VERSION ""

NS_ :

BS_:

BU_:

BO_ 3221225472 VECTOR__INDEPENDENT_SIG_MSG: 0 Vector__XXX
 SG_ Unknown_176_4 : 32|8@1+ (1,0) [0|0] "" Vector__XXX
 SG_ NewSignal_0024 : 32|8@1+ (1,0) [0|0] "" Vector__XXX
 SG_ Unknown_215_6 : 0|8@1+ (1,0) [0|0] "" Vector__XXX

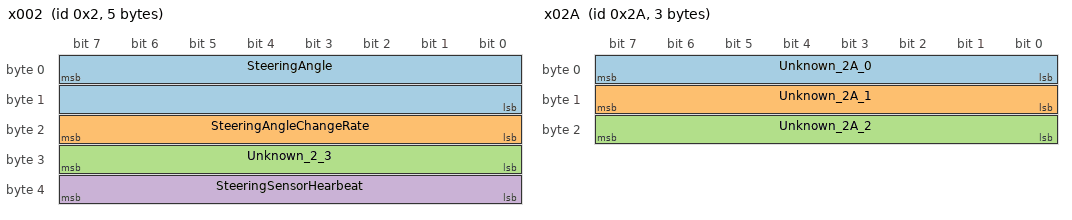
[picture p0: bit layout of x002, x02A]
BO_ 2 x002: 5 Vector__XXX
 SG_ SteeringAngle : 7|16@0+ (1,0) [0|0] "ddeg" Vector__XXX
 SG_ SteeringAngleChangeRate : 23|8@0+ (1,0) [0|0] "" Vector__XXX
 SG_ Unknown_2_3 : 31|8@0+ (1,0) [0|0] "" Vector__XXX
 SG_ SteeringSensorHearbeat : 39|8@0+ (1,0) [0|0] "" Vector__XXX

BO_ 42 x02A: 3 Vector__XXX
 SG_ Unknown_2A_0 : 0|8@1+ (1,0) [0|0] "" Vector__XXX
 SG_ Unknown_2A_1 : 8|8@1+ (1,0) [0|0] "" Vector__XXX
 SG_ Unknown_2A_2 : 16|8@1+ (1,0) [0|0] "" Vector__XXX

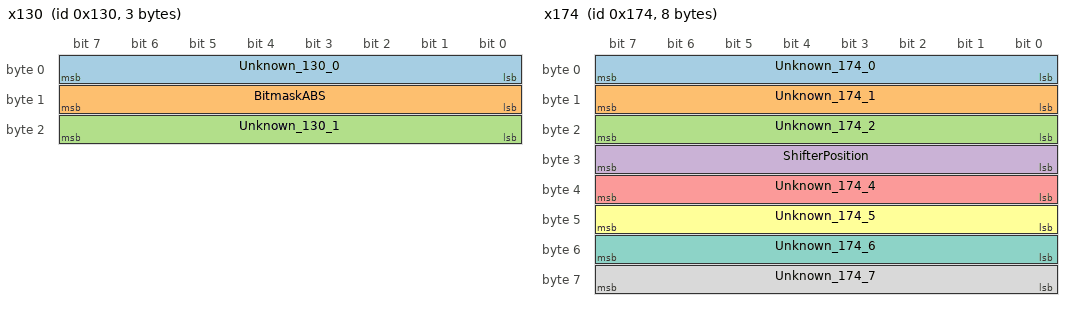
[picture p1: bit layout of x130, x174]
BO_ 304 x130: 3 Vector__XXX
 SG_ Unknown_130_0 : 0|8@1+ (1,0) [0|0] "" Vector__XXX
 SG_ BitmaskABS : 8|8@1+ (1,0) [0|0] "" Vector__XXX
 SG_ Unknown_130_1 : 16|8@1+ (1,0) [0|0] "" Vector__XXX

BO_ 372 x174: 8 Vector__XXX
 SG_ Unknown_174_0 : 0|8@1+ (1,0) [0|0] "" Vector__XXX
 SG_ Unknown_174_1 : 8|8@1+ (1,0) [0|0] "" Vector__XXX
 SG_ Unknown_174_2 : 16|8@1+ (1,0) [0|0] "" Vector__XXX
 SG_ ShifterPosition : 24|8@1+ (1,0) [0|0] "" Vector__XXX
 SG_ Unknown_174_4 : 32|8@1+ (1,0) [0|0] "" Vector__XXX
 SG_ Unknown_174_5 : 40|8@1+ (1,0) [0|0] "" Vector__XXX
 SG_ Unknown_174_6 : 48|8@1+ (1,0) [0|0] "" Vector__XXX
 SG_ Unknown_174_7 : 56|8@1+ (1,0) [0|0] "" Vector__XXX

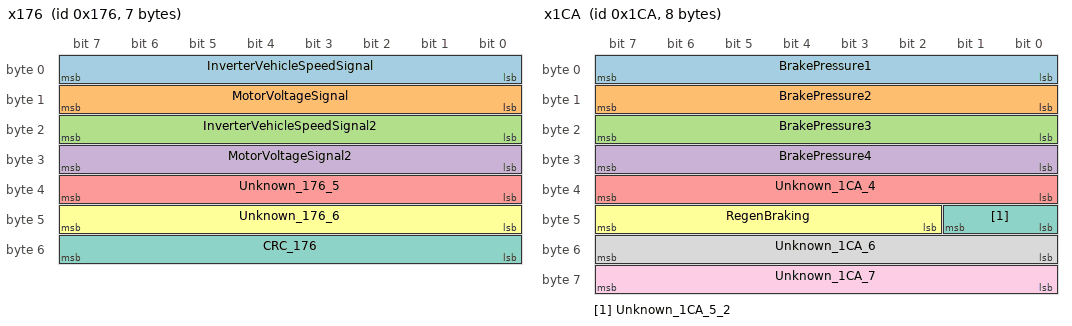
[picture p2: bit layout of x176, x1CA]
BO_ 374 x176: 7 Vector__XXX
 SG_ InverterVehicleSpeedSignal : 0|8@1+ (1,0) [0|0] "" Vector__XXX
 SG_ MotorVoltageSignal : 8|8@1+ (1,0) [0|0] "" Vector__XXX
 SG_ InverterVehicleSpeedSignal2 : 16|8@1+ (1,0) [0|0] "" Vector__XXX
 SG_ MotorVoltageSignal2 : 24|8@1+ (1,0) [0|0] "" Vector__XXX
 SG_ Unknown_176_5 : 32|8@1+ (1,0) [0|0] "" Vector__XXX
 SG_ Unknown_176_6 : 40|8@1+ (1,0) [0|0] "" Vector__XXX
 SG_ CRC_176 : 48|8@1+ (1,0) [0|0] "" Vector__XXX

BO_ 384 x180: 8 Vector__XXX
 SG_ Unknown_180_0 : 0|8@1+ (1,0) [0|0] "" Vector__XXX
 SG_ Unknown_180_1 : 8|8@1+ (1,0) [0|0] "" Vector__XXX
 SG_ MotorAmp : 23|16@0+ (1,0) [0|0] "" Vector__XXX
 SG_ MotorAmpAlternative : 32|8@1+ (1,0) [0|0] "" Vector__XXX
 SG_ ThrottlePosition : 40|8@1+ (1,0) [0|0] "" Vector__XXX
 SG_ Unknown_180_5 : 48|8@1+ (1,0) [0|0] "" Vector__XXX
 SG_ Unknown_180_6 : 56|8@1+ (1,0) [0|0] "" Vector__XXX
 SG_ Unknown_180_7 : 0|8@1+ (1,0) [0|0] "" Vector__XXX

BO_ 458 x1CA: 8 Vector__XXX
 SG_ BrakePressure1 : 0|8@1+ (1,0) [0|0] "" Vector__XXX
 SG_ BrakePressure2 : 8|8@1+ (1,0) [0|0] "" Vector__XXX
 SG_ BrakePressure3 : 16|8@1+ (1,0) [0|0] "" Vector__XXX
 SG_ BrakePressure4 : 24|8@1+ (1,0) [0|0] "" Vector__XXX
 SG_ Unknown_1CA_4 : 32|8@1+ (1,0) [0|0] "" Vector__XXX
 SG_ RegenBraking : 42|6@1+ (1,0) [0|0] "" Vector__XXX
 SG_ Unknown_1CA_5_2 : 40|2@1+ (1,0) [0|0] "" Vector__XXX
 SG_ Unknown_1CA_6 : 48|8@1+ (1,0) [0|0] "" Vector__XXX
 SG_ Unknown_1CA_7 : 56|8@1+ (1,0) [0|0] "" Vector__XXX

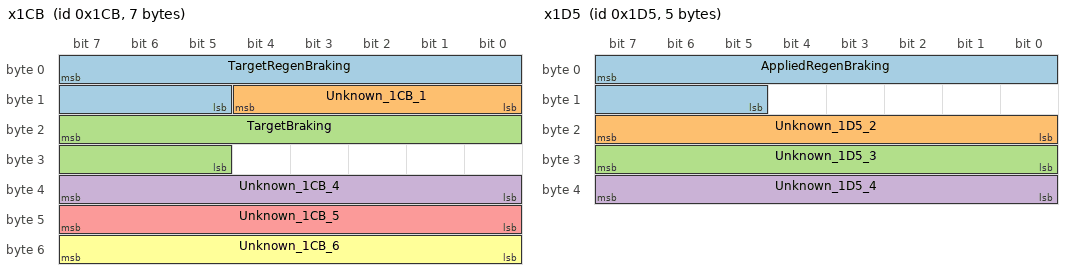
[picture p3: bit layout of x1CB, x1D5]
BO_ 459 x1CB: 7 Vector__XXX
 SG_ TargetRegenBraking : 7|11@0+ (1,0) [0|0] "" Vector__XXX
 SG_ Unknown_1CB_1 : 8|5@1+ (1,0) [0|0] "" Vector__XXX
 SG_ TargetBraking : 23|11@0+ (1,0) [0|0] "" Vector__XXX
 SG_ Unknown_1CB_4 : 32|8@1+ (1,0) [0|0] "" Vector__XXX
 SG_ Unknown_1CB_5 : 40|8@1+ (1,0) [0|0] "" Vector__XXX
 SG_ Unknown_1CB_6 : 48|8@1+ (1,0) [0|0] "" Vector__XXX

BO_ 469 x1D5: 5 Vector__XXX
 SG_ AppliedRegenBraking : 7|11@0+ (1,0) [0|0] "" Vector__XXX
 SG_ Unknown_1D5_2 : 16|8@1+ (1,0) [0|0] "" Vector__XXX
 SG_ Unknown_1D5_3 : 24|8@1+ (1,0) [0|0] "" Vector__XXX
 SG_ Unknown_1D5_4 : 32|8@1+ (1,0) [0|0] "" Vector__XXX

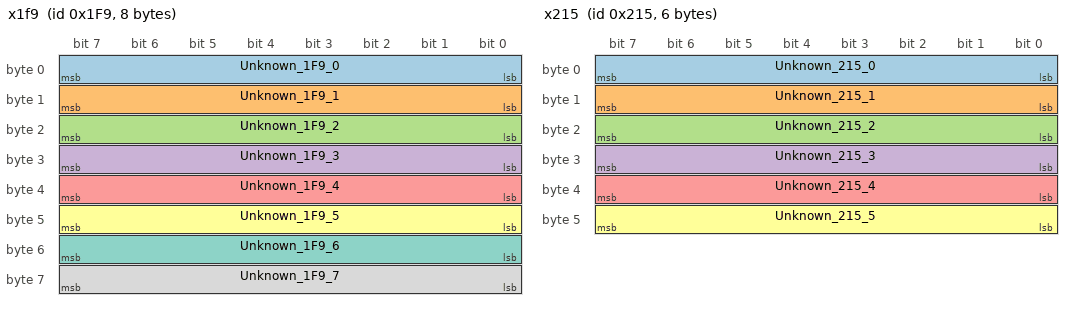
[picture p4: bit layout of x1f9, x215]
BO_ 505 x1f9: 8 Vector__XXX
 SG_ Unknown_1F9_0 : 0|8@1+ (1,0) [0|0] "" Vector__XXX
 SG_ Unknown_1F9_1 : 8|8@1+ (1,0) [0|0] "" Vector__XXX
 SG_ Unknown_1F9_2 : 16|8@1+ (1,0) [0|0] "" Vector__XXX
 SG_ Unknown_1F9_3 : 24|8@1+ (1,0) [0|0] "" Vector__XXX
 SG_ Unknown_1F9_4 : 32|8@1+ (1,0) [0|0] "" Vector__XXX
 SG_ Unknown_1F9_5 : 40|8@1+ (1,0) [0|0] "" Vector__XXX
 SG_ Unknown_1F9_6 : 48|8@1+ (1,0) [0|0] "" Vector__XXX
 SG_ Unknown_1F9_7 : 56|8@1+ (1,0) [0|0] "" Vector__XXX

BO_ 533 x215: 6 Vector__XXX
 SG_ Unknown_215_0 : 0|8@1+ (1,0) [0|0] "" Vector__XXX
 SG_ Unknown_215_1 : 8|8@1+ (1,0) [0|0] "" Vector__XXX
 SG_ Unknown_215_2 : 16|8@1+ (1,0) [0|0] "" Vector__XXX
 SG_ Unknown_215_3 : 24|8@1+ (1,0) [0|0] "" Vector__XXX
 SG_ Unknown_215_4 : 32|8@1+ (1,0) [0|0] "" Vector__XXX
 SG_ Unknown_215_5 : 40|8@1+ (1,0) [0|0] "" Vector__XXX

BO_ 534 x216: 2 Vector__XXX
 SG_ Unknown_216_0 : 0|8@1+ (1,0) [0|0] "" Vector__XXX
 SG_ Unknown_216_1 : 8|8@1+ (1,0) [0|0] "" Vector__XXX

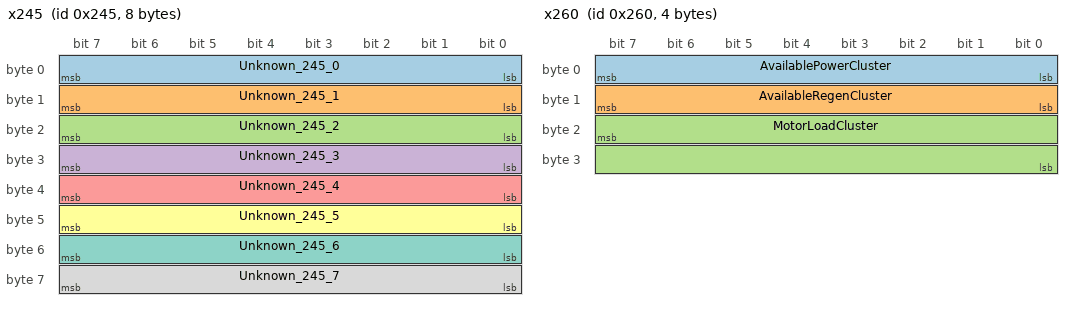
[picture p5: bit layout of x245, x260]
BO_ 581 x245: 8 Vector__XXX
 SG_ Unknown_245_0 : 0|8@1+ (1,0) [0|0] "" Vector__XXX
 SG_ Unknown_245_1 : 8|8@1+ (1,0) [0|0] "" Vector__XXX
 SG_ Unknown_245_2 : 16|8@1+ (1,0) [0|0] "" Vector__XXX
 SG_ Unknown_245_3 : 24|8@1+ (1,0) [0|0] "" Vector__XXX
 SG_ Unknown_245_4 : 32|8@1+ (1,0) [0|0] "" Vector__XXX
 SG_ Unknown_245_5 : 40|8@1+ (1,0) [0|0] "" Vector__XXX
 SG_ Unknown_245_6 : 48|8@1+ (1,0) [0|0] "" Vector__XXX
 SG_ Unknown_245_7 : 56|8@1+ (1,0) [0|0] "" Vector__XXX

BO_ 608 x260: 4 Vector__XXX
 SG_ AvailablePowerCluster : 0|8@1+ (1,0) [0|90] "kW" Vector__XXX
 SG_ AvailableRegenCluster : 8|8@1+ (1,0) [0|50] "kW" Vector__XXX
 SG_ MotorLoadCluster : 23|16@0+ (1,0) [100|16000] "" Vector__XXX

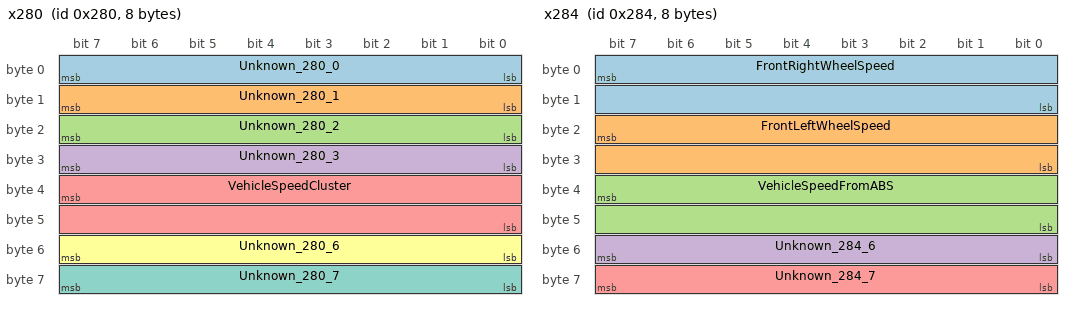
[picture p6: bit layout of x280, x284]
BO_ 640 x280: 8 Vector__XXX
 SG_ Unknown_280_0 : 0|8@1+ (1,0) [0|0] "" Vector__XXX
 SG_ Unknown_280_1 : 8|8@1+ (1,0) [0|0] "" Vector__XXX
 SG_ Unknown_280_2 : 16|8@1+ (1,0) [0|0] "" Vector__XXX
 SG_ Unknown_280_3 : 24|8@1+ (1,0) [0|0] "" Vector__XXX
 SG_ VehicleSpeedCluster : 39|16@0+ (1,0) [0|0] "" Vector__XXX
 SG_ Unknown_280_6 : 48|8@1+ (1,0) [0|0] "" Vector__XXX
 SG_ Unknown_280_7 : 56|8@1+ (1,0) [0|0] "" Vector__XXX

BO_ 644 x284: 8 Vector__XXX
 SG_ FrontRightWheelSpeed : 7|16@0+ (1,0) [0|0] "" Vector__XXX
 SG_ FrontLeftWheelSpeed : 23|16@0+ (1,0) [0|0] "" Vector__XXX
 SG_ VehicleSpeedFromABS : 39|16@0+ (1,0) [0|0] "" Vector__XXX
 SG_ Unknown_284_6 : 48|8@1+ (1,0) [0|0] "" Vector__XXX
 SG_ Unknown_284_7 : 56|8@1+ (1,0) [0|0] "" Vector__XXX

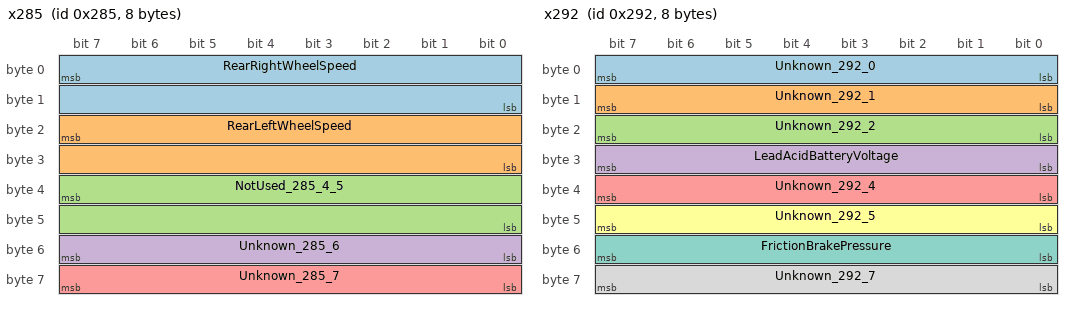
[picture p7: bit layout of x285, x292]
BO_ 645 x285: 8 Vector__XXX
 SG_ RearRightWheelSpeed : 7|16@0+ (1,0) [0|0] "" Vector__XXX
 SG_ RearLeftWheelSpeed : 23|16@0+ (1,0) [0|0] "" Vector__XXX
 SG_ NotUsed_285_4_5 : 39|16@0+ (1,0) [0|0] "" Vector__XXX
 SG_ Unknown_285_6 : 48|8@1+ (1,0) [0|0] "" Vector__XXX
 SG_ Unknown_285_7 : 56|8@1+ (1,0) [0|0] "" Vector__XXX

BO_ 658 x292: 8 Vector__XXX
 SG_ Unknown_292_0 : 0|8@1+ (1,0) [0|0] "" Vector__XXX
 SG_ Unknown_292_1 : 8|8@1+ (1,0) [0|0] "" Vector__XXX
 SG_ Unknown_292_2 : 16|8@1+ (1,0) [0|0] "" Vector__XXX
 SG_ LeadAcidBatteryVoltage : 24|8@1+ (1,0) [0|150] "dV" Vector__XXX
 SG_ Unknown_292_4 : 32|8@1+ (1,0) [0|0] "" Vector__XXX
 SG_ Unknown_292_5 : 40|8@1+ (1,0) [0|0] "" Vector__XXX
 SG_ FrictionBrakePressure : 48|8@1+ (1,0) [0|255] "" Vector__XXX
 SG_ Unknown_292_7 : 56|8@1+ (1,0) [0|0] "" Vector__XXX

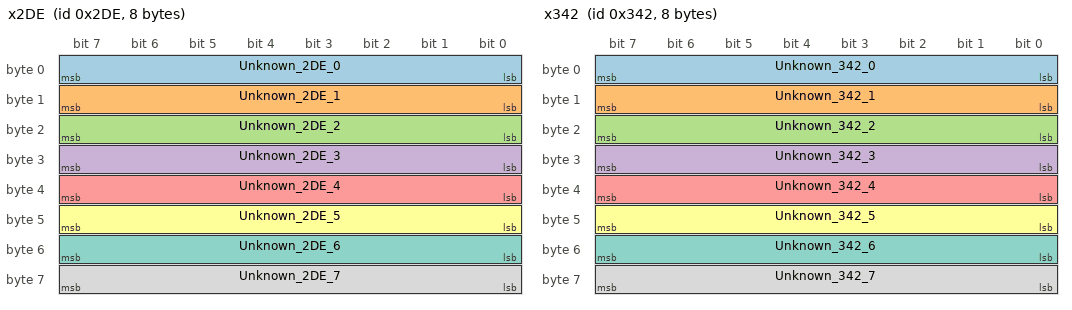
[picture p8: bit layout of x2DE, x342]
BO_ 734 x2DE: 8 Vector__XXX
 SG_ Unknown_2DE_0 : 0|8@1+ (1,0) [0|0] "" Vector__XXX
 SG_ Unknown_2DE_1 : 8|8@1+ (1,0) [0|0] "" Vector__XXX
 SG_ Unknown_2DE_2 : 16|8@1+ (1,0) [0|0] "" Vector__XXX
 SG_ Unknown_2DE_3 : 24|8@1+ (1,0) [0|0] "" Vector__XXX
 SG_ Unknown_2DE_4 : 32|8@1+ (1,0) [0|0] "" Vector__XXX
 SG_ Unknown_2DE_5 : 40|8@1+ (1,0) [0|0] "" Vector__XXX
 SG_ Unknown_2DE_6 : 48|8@1+ (1,0) [0|0] "" Vector__XXX
 SG_ Unknown_2DE_7 : 56|8@1+ (1,0) [0|0] "" Vector__XXX

BO_ 768 x300: 1 Vector__XXX
 SG_ SteeringWheelForce : 0|8@1+ (1,0) [0|0] "" Vector__XXX

BO_ 834 x342: 8 Vector__XXX
 SG_ Unknown_342_0 : 0|8@1+ (1,0) [0|0] "" Vector__XXX
 SG_ Unknown_342_1 : 8|8@1+ (1,0) [0|0] "" Vector__XXX
 SG_ Unknown_342_2 : 16|8@1+ (1,0) [0|0] "" Vector__XXX
 SG_ Unknown_342_3 : 24|8@1+ (1,0) [0|0] "" Vector__XXX
 SG_ Unknown_342_4 : 32|8@1+ (1,0) [0|0] "" Vector__XXX
 SG_ Unknown_342_5 : 40|8@1+ (1,0) [0|0] "" Vector__XXX
 SG_ Unknown_342_6 : 48|8@1+ (1,0) [0|0] "" Vector__XXX
 SG_ Unknown_342_7 : 56|8@1+ (1,0) [0|0] "" Vector__XXX

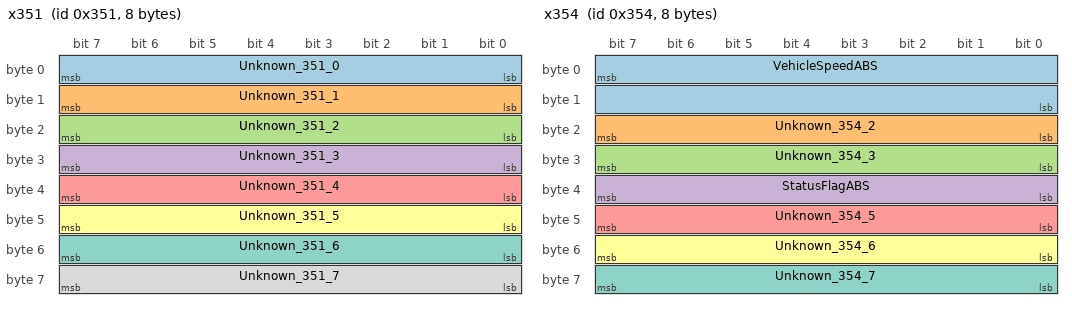
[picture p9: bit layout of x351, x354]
BO_ 849 x351: 8 Vector__XXX
 SG_ Unknown_351_0 : 0|8@1+ (1,0) [0|0] "" Vector__XXX
 SG_ Unknown_351_1 : 8|8@1+ (1,0) [0|0] "" Vector__XXX
 SG_ Unknown_351_2 : 16|8@1+ (1,0) [0|0] "" Vector__XXX
 SG_ Unknown_351_3 : 24|8@1+ (1,0) [0|0] "" Vector__XXX
 SG_ Unknown_351_4 : 32|8@1+ (1,0) [0|0] "" Vector__XXX
 SG_ Unknown_351_5 : 40|8@1+ (1,0) [0|0] "" Vector__XXX
 SG_ Unknown_351_6 : 48|8@1+ (1,0) [0|0] "" Vector__XXX
 SG_ Unknown_351_7 : 56|8@1+ (1,0) [0|0] "" Vector__XXX

BO_ 852 x354: 8 Vector__XXX
 SG_ VehicleSpeedABS : 7|16@0+ (1,0) [0|0] "" Vector__XXX
 SG_ Unknown_354_2 : 16|8@1+ (1,0) [0|0] "" Vector__XXX
 SG_ Unknown_354_3 : 24|8@1+ (1,0) [0|0] "" Vector__XXX
 SG_ StatusFlagABS : 32|8@1+ (1,0) [0|0] "" Vector__XXX
 SG_ Unknown_354_5 : 40|8@1+ (1,0) [0|0] "" Vector__XXX
 SG_ Unknown_354_6 : 48|8@1+ (1,0) [0|0] "" Vector__XXX
 SG_ Unknown_354_7 : 56|8@1+ (1,0) [0|0] "" Vector__XXX

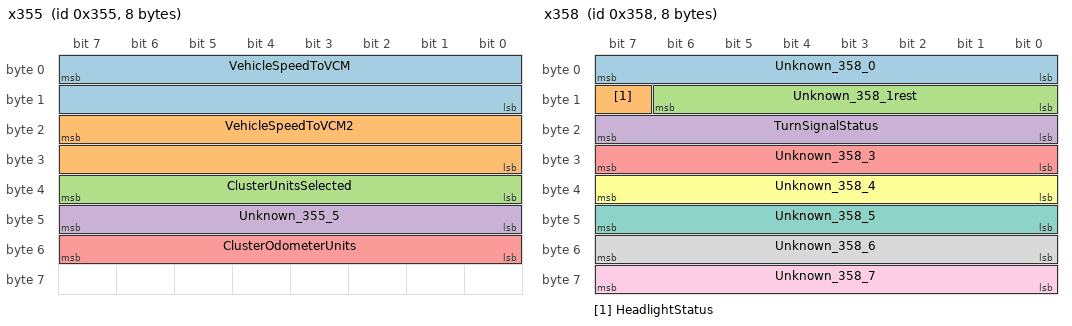
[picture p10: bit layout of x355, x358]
BO_ 853 x355: 8 Vector__XXX
 SG_ VehicleSpeedToVCM : 7|16@0+ (1,0) [0|0] "" Vector__XXX
 SG_ VehicleSpeedToVCM2 : 23|16@0+ (1,0) [0|0] "" Vector__XXX
 SG_ ClusterUnitsSelected : 32|8@1+ (1,0) [0|0] "" Vector__XXX
 SG_ Unknown_355_5 : 40|8@1+ (1,0) [0|0] "" Vector__XXX
 SG_ ClusterOdometerUnits : 48|8@1+ (1,0) [0|0] "" Vector__XXX

BO_ 856 x358: 8 Vector__XXX
 SG_ Unknown_358_0 : 0|8@1+ (1,0) [0|0] "" Vector__XXX
 SG_ HeadlightStatus : 15|1@1+ (1,0) [0|0] "" Vector__XXX
 SG_ Unknown_358_1rest : 8|7@1+ (1,0) [0|0] "" Vector__XXX
 SG_ TurnSignalStatus : 16|8@1+ (1,0) [0|0] "" Vector__XXX
 SG_ Unknown_358_3 : 24|8@1+ (1,0) [0|0] "" Vector__XXX
 SG_ Unknown_358_4 : 32|8@1+ (1,0) [0|0] "" Vector__XXX
 SG_ Unknown_358_5 : 40|8@1+ (1,0) [0|0] "" Vector__XXX
 SG_ Unknown_358_6 : 48|8@1+ (1,0) [0|0] "" Vector__XXX
 SG_ Unknown_358_7 : 56|8@1+ (1,0) [0|0] "" Vector__XXX

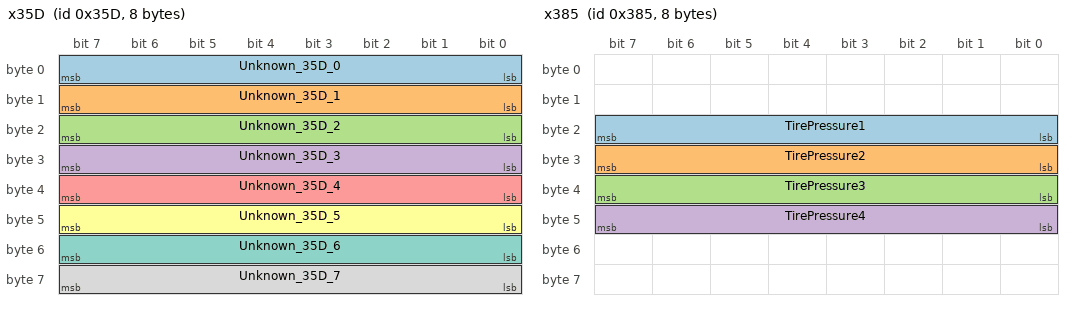
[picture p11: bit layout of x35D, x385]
BO_ 861 x35D: 8 Vector__XXX
 SG_ Unknown_35D_0 : 0|8@1+ (1,0) [0|0] "" Vector__XXX
 SG_ Unknown_35D_1 : 8|8@1+ (1,0) [0|0] "" Vector__XXX
 SG_ Unknown_35D_2 : 16|8@1+ (1,0) [0|0] "" Vector__XXX
 SG_ Unknown_35D_3 : 24|8@1+ (1,0) [0|0] "" Vector__XXX
 SG_ Unknown_35D_4 : 32|8@1+ (1,0) [0|0] "" Vector__XXX
 SG_ Unknown_35D_5 : 40|8@1+ (1,0) [0|0] "" Vector__XXX
 SG_ Unknown_35D_6 : 48|8@1+ (1,0) [0|0] "" Vector__XXX
 SG_ Unknown_35D_7 : 56|8@1+ (1,0) [0|0] "" Vector__XXX

BO_ 901 x385: 8 Vector__XXX
 SG_ TirePressure1 : 16|8@1+ (1,0) [0|0] "" Vector__XXX
 SG_ TirePressure2 : 24|8@1+ (1,0) [0|0] "" Vector__XXX
 SG_ TirePressure3 : 32|8@1+ (1,0) [0|0] "" Vector__XXX
 SG_ TirePressure4 : 40|8@1+ (1,0) [0|0] "" Vector__XXX

BO_ 1057 x421: 1 Vector__XXX
 SG_ DashShifterPosition : 0|8@1+ (1,0) [0|0] "" Vector__XXX

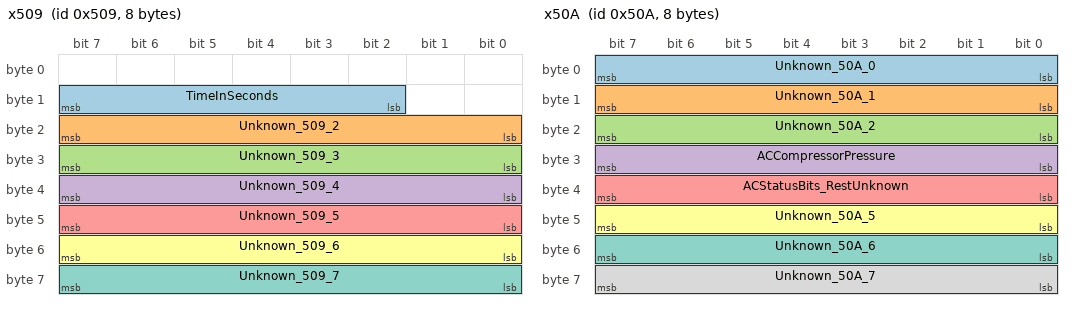
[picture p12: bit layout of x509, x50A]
BO_ 1289 x509: 8 Vector__XXX
 SG_ TimeInSeconds : 10|6@1+ (1,0) [0|59] "" Vector__XXX
 SG_ Unknown_509_2 : 16|8@1+ (1,0) [0|0] "" Vector__XXX
 SG_ Unknown_509_3 : 24|8@1+ (1,0) [0|0] "" Vector__XXX
 SG_ Unknown_509_4 : 32|8@1+ (1,0) [0|0] "" Vector__XXX
 SG_ Unknown_509_5 : 40|8@1+ (1,0) [0|0] "" Vector__XXX
 SG_ Unknown_509_6 : 48|8@1+ (1,0) [0|0] "" Vector__XXX
 SG_ Unknown_509_7 : 56|8@1+ (1,0) [0|0] "" Vector__XXX

BO_ 1290 x50A: 8 Vector__XXX
 SG_ Unknown_50A_0 : 0|8@1+ (1,0) [0|0] "" Vector__XXX
 SG_ Unknown_50A_1 : 8|8@1+ (1,0) [0|0] "" Vector__XXX
 SG_ Unknown_50A_2 : 16|8@1+ (1,0) [0|0] "" Vector__XXX
 SG_ ACCompressorPressure : 24|8@1+ (1,0) [0|0] "" Vector__XXX
 SG_ ACStatusBits_RestUnknown : 32|8@1+ (1,0) [0|0] "" Vector__XXX
 SG_ Unknown_50A_5 : 40|8@1+ (1,0) [0|0] "" Vector__XXX
 SG_ Unknown_50A_6 : 48|8@1+ (1,0) [0|0] "" Vector__XXX
 SG_ Unknown_50A_7 : 56|8@1+ (1,0) [0|0] "" Vector__XXX

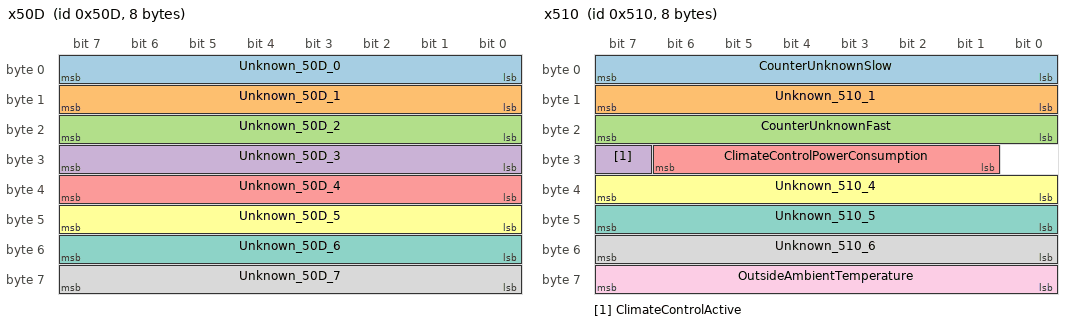
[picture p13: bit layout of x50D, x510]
BO_ 1293 x50D: 8 Vector__XXX
 SG_ Unknown_50D_0 : 0|8@1+ (1,0) [0|0] "" Vector__XXX
 SG_ Unknown_50D_1 : 8|8@1+ (1,0) [0|0] "" Vector__XXX
 SG_ Unknown_50D_2 : 16|8@1+ (1,0) [0|0] "" Vector__XXX
 SG_ Unknown_50D_3 : 24|8@1+ (1,0) [0|0] "" Vector__XXX
 SG_ Unknown_50D_4 : 32|8@1+ (1,0) [0|0] "" Vector__XXX
 SG_ Unknown_50D_5 : 40|8@1+ (1,0) [0|0] "" Vector__XXX
 SG_ Unknown_50D_6 : 48|8@1+ (1,0) [0|0] "" Vector__XXX
 SG_ Unknown_50D_7 : 56|8@1+ (1,0) [0|0] "" Vector__XXX

BO_ 1296 x510: 8 Vector__XXX
 SG_ CounterUnknownSlow : 0|8@1+ (1,0) [0|255] "" Vector__XXX
 SG_ Unknown_510_1 : 8|8@1+ (1,0) [0|0] "" Vector__XXX
 SG_ CounterUnknownFast : 16|8@1+ (1,0) [0|255] "" Vector__XXX
 SG_ ClimateControlActive : 31|1@1+ (1,0) [0|0] "" Vector__XXX
 SG_ ClimateControlPowerConsumption : 25|6@1+ (1,0) [0|0] "0.25kW" Vector__XXX
 SG_ Unknown_510_4 : 32|8@1+ (1,0) [0|0] "" Vector__XXX
 SG_ Unknown_510_5 : 40|8@1+ (1,0) [0|0] "" Vector__XXX
 SG_ Unknown_510_6 : 48|8@1+ (1,0) [0|0] "" Vector__XXX
 SG_ OutsideAmbientTemperature : 56|8@1+ (1,0) [0|255] "" Vector__XXX

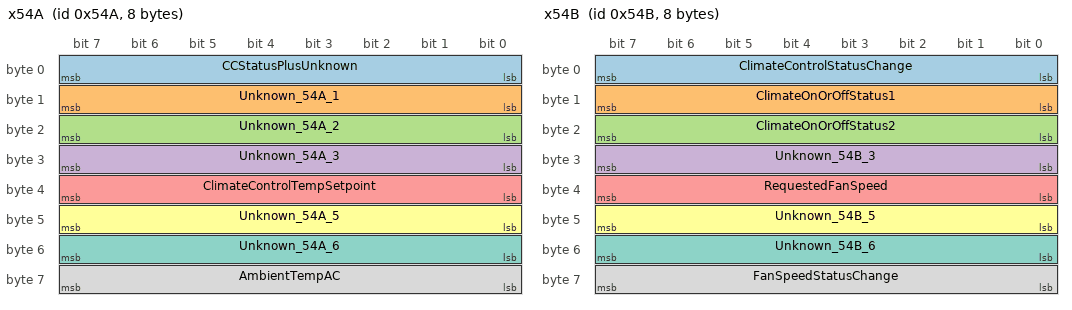
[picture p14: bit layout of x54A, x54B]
BO_ 1354 x54A: 8 Vector__XXX
 SG_ CCStatusPlusUnknown : 0|8@1+ (1,0) [0|0] "" Vector__XXX
 SG_ Unknown_54A_1 : 8|8@1+ (1,0) [0|0] "" Vector__XXX
 SG_ Unknown_54A_2 : 16|8@1+ (1,0) [0|0] "" Vector__XXX
 SG_ Unknown_54A_3 : 24|8@1+ (1,0) [0|0] "" Vector__XXX
 SG_ ClimateControlTempSetpoint : 32|8@1+ (1,0) [0|0] "" Vector__XXX
 SG_ Unknown_54A_5 : 40|8@1+ (1,0) [0|0] "" Vector__XXX
 SG_ Unknown_54A_6 : 48|8@1+ (1,0) [0|0] "" Vector__XXX
 SG_ AmbientTempAC : 56|8@1+ (1,0) [0|0] "" Vector__XXX

BO_ 1355 x54B: 8 Vector__XXX
 SG_ ClimateControlStatusChange : 0|8@1+ (1,0) [0|0] "" Vector__XXX
 SG_ ClimateOnOrOffStatus1 : 8|8@1+ (1,0) [0|0] "" Vector__XXX
 SG_ ClimateOnOrOffStatus2 : 16|8@1+ (1,0) [0|0] "" Vector__XXX
 SG_ Unknown_54B_3 : 24|8@1+ (1,0) [0|0] "" Vector__XXX
 SG_ RequestedFanSpeed : 32|8@1+ (1,0) [0|0] "" Vector__XXX
 SG_ Unknown_54B_5 : 40|8@1+ (1,0) [0|0] "" Vector__XXX
 SG_ Unknown_54B_6 : 48|8@1+ (1,0) [0|0] "" Vector__XXX
 SG_ FanSpeedStatusChange : 56|8@1+ (1,0) [0|0] "" Vector__XXX

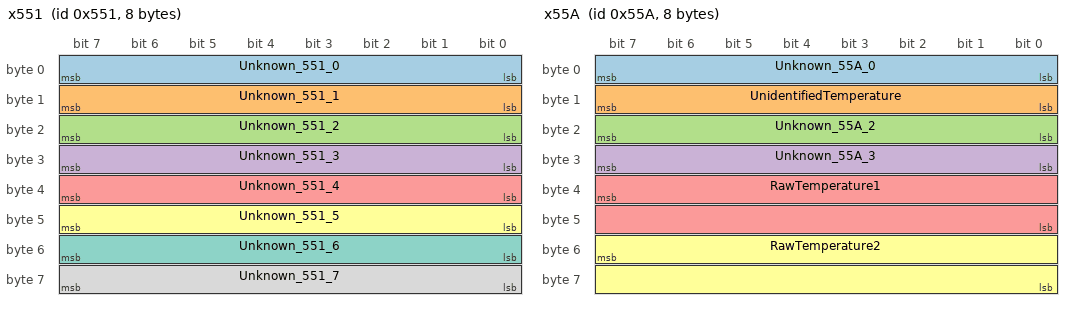
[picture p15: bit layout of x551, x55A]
BO_ 1361 x551: 8 Vector__XXX
 SG_ Unknown_551_0 : 0|8@1+ (1,0) [0|0] "" Vector__XXX
 SG_ Unknown_551_1 : 8|8@1+ (1,0) [0|0] "" Vector__XXX
 SG_ Unknown_551_2 : 16|8@1+ (1,0) [0|0] "" Vector__XXX
 SG_ Unknown_551_3 : 24|8@1+ (1,0) [0|0] "" Vector__XXX
 SG_ Unknown_551_4 : 32|8@1+ (1,0) [0|0] "" Vector__XXX
 SG_ Unknown_551_5 : 40|8@1+ (1,0) [0|0] "" Vector__XXX
 SG_ Unknown_551_6 : 48|8@1+ (1,0) [0|0] "" Vector__XXX
 SG_ Unknown_551_7 : 56|8@1+ (1,0) [0|0] "" Vector__XXX

BO_ 1370 x55A: 8 Vector__XXX
 SG_ Unknown_55A_0 : 0|8@1+ (1,0) [0|0] "" Vector__XXX
 SG_ UnidentifiedTemperature : 8|8@1+ (1,0) [0|0] "" Vector__XXX
 SG_ Unknown_55A_2 : 16|8@1+ (1,0) [0|0] "" Vector__XXX
 SG_ Unknown_55A_3 : 24|8@1+ (1,0) [0|0] "" Vector__XXX
 SG_ RawTemperature1 : 39|16@0+ (1,0) [0|0] "" Vector__XXX
 SG_ RawTemperature2 : 55|16@0+ (1,0) [0|0] "" Vector__XXX

BO_ 1449 x5A9: 8 Vector__XXX
 SG_ Unknown_5A9_0 : 0|8@1+ (1,0) [0|0] "" Vector__XXX

CM_ BO_ 2 "???
Steering angle sensor signal. Goes to AV unit, Brake, and ABS modules";
CM_ SG_ 2 SteeringAngle "Steering Angle LSB:MSB
Left is negative
Degrees = value/10 (3600 = 360.0deg)";
CM_ SG_ 2 Unknown_2_3 "07?";
CM_ SG_ 2 SteeringSensorHearbeat "Heartbeat or CRC, yet to be confirmed
Very active (00-ff)";
CM_ BO_ 42 "???";
CM_ SG_ 42 Unknown_2A_0 "Always 0?";
CM_ SG_ 42 Unknown_2A_1 "Always 0?";
CM_ SG_ 42 Unknown_2A_2 "Always 0?";
CM_ BO_ 304 "ABS Module";
CM_ SG_ 304 BitmaskABS "Bit5 = 1 = Traction control off?";
CM_ BO_ 372 "Probably VCM Relay from eshift on EV CAN";
CM_ SG_ 372 ShifterPosition "AA:Park/Neutral BB:Drive 99:Reverse";
CM_ SG_ 372 Unknown_174_4 "00...0F";
CM_ BO_ 374 "Might be VCM relay of Inverter message of motor RPM?";
CM_ SG_ 374 InverterVehicleSpeedSignal "???scalar of 0.0725 seems to translate roughly to mph; absolute (always positive)";
CM_ SG_ 374 MotorVoltageSignal "???might be motor volts instead of speed
Should this message be connected with the first?";
CM_ SG_ 374 InverterVehicleSpeedSignal2 "???scalar of .0091 seems to translate roughly to mph; always positive";
CM_ SG_ 374 MotorVoltageSignal2 "??might be motor volts instead of speed
Should this message be connected to the above?";
CM_ SG_ 374 Unknown_176_5 "00";
CM_ SG_ 374 Unknown_176_6 "00";
CM_ SG_ 374 CRC_176 "00...0F";
CM_ BO_ 384 "VCM";
CM_ SG_ 384 MotorAmp "2's compliment; Tracks power when multiplied with 176.23 and divided by ~30 or 176.01 divided by ~3.6";
CM_ SG_ 384 MotorAmpAlternative "Very similar to 180:B2/3 expect is clipped and decays to zero during regen";
CM_ BO_ 458 "Brake Control Module
(Not present on MY2013)";
CM_ BO_ 459 "Brake Control Module";
CM_ SG_ 459 TargetRegenBraking "Appears to be target regen before getting qualified by charge level, etc.";
CM_ SG_ 459 TargetBraking "Units track motor amps in m180.23";
CM_ BO_ 469 "Brake Control Module?";
CM_ BO_ 505 "VCM?";
CM_ BO_ 533 "? Key system ?";
CM_ BO_ 534 "Related to proximity key? 
I saw these messages on CAR can when there shouldn't be activity but I was walking near the car.";
CM_ BO_ 581 "???";
CM_ SG_ 581 Unknown_245_4 "Just ramps and wraps";
CM_ BO_ 608 "VCM to cluster?";
CM_ SG_ 608 AvailablePowerCluster "50-5A (80-90kW) observed in normal driving, decays to 31 (51kW) around turtle";
CM_ SG_ 608 AvailableRegenCluster "Used to generate regen bubbles with hysteresis.  Bubbles turn at @ 6,C,12,&18 and turn off at 0,6,C, & 12 respectively (6,12,18,24kW)";
CM_ SG_ 608 MotorLoadCluster "Units are unknown (100-16000) - doesn't include accessory- It is probably the dash power display \"inner\" bubbles. Observe byte 2 at 0x19 and byte 3 at 00 when at idle.";
CM_ BO_ 640 "VCM to cluster? or vice versa?";
CM_ SG_ 640 Unknown_280_0 "Some activity here even when car is off, might be related to other dash lights (like the red key light)";
CM_ SG_ 640 Unknown_280_1 "Some activity here even when car is off, might be related to other dash lights (like the red key light)
370Z had seatbelt status as byte 0 bit 0. Need to verify. Could probably sync video of startup and CAN log to get the various lights and bytes used";
CM_ SG_ 640 VehicleSpeedCluster ".0062 scalar seems to match mph";
CM_ BO_ 644 "ABS Module

Common with other Nissans such as 370Z";
CM_ SG_ 644 FrontRightWheelSpeed ".0118 scalar";
CM_ SG_ 644 FrontLeftWheelSpeed ".0118 scalar";
CM_ SG_ 644 VehicleSpeedFromABS ".0245";
CM_ BO_ 645 "ABS Module

Common with other Nissans such as 370Z";
CM_ SG_ 645 NotUsed_285_4_5 "284 contains speed, this message left empty";
CM_ BO_ 658 "ABS Module

Common with other Nissans such as 370Z";
CM_ SG_ 658 LeadAcidBatteryVoltage "Example, 7F = 12.7V";
CM_ SG_ 658 FrictionBrakePressure "Measured to provide the same braking force as 55 regen motor amps (cc180.23) per tick";
CM_ BO_ 734 "???";
CM_ SG_ 734 Unknown_2DE_6 "03";
CM_ SG_ 734 Unknown_2DE_7 "CA";
CM_ BO_ 768 "Steering Angle Sensor";
CM_ SG_ 768 SteeringWheelForce "Steering force applied to wheel";
CM_ BO_ 834 "? Key system ?

370Z notes this is related to key fob info";
CM_ SG_ 834 Unknown_342_0 "Only saw once in a log about the time I left to go inside.  Maybe related to the \"key is leaving the car while on\" chirp?";
CM_ BO_ 849 "???";
CM_ BO_ 852 "ABS Module

Same as 370Z";
CM_ SG_ 852 StatusFlagABS "0x40 when traction control is off";
CM_ BO_ 853 "Instrument cluster to VCM (Length?)

On my 2012 this is a 7 byte message (2011 8 byte?) 2013 ? lenght? This database is for AZE0";
CM_ SG_ 853 ClusterUnitsSelected "Selected dash miles/eff units

0x00=km;0x20=mi";
CM_ SG_ 853 ClusterOdometerUnits "Dash odometer units

0x60=miles;0x40=km";
CM_ BO_ 856 "Body Control Module";
CM_ SG_ 856 HeadlightStatus "1 = ON, changes with manual control or auto";
CM_ SG_ 856 TurnSignalStatus "See value table";
CM_ BO_ 861 "Body Control Module (Please investigate)

Possibly Similar to 370z, if so there's wiper data here";
CM_ BO_ 901 "Tire Pressure Monitoring System";
CM_ BO_ 1057 "VCM relay from shifter on EV bus to Instrument panel and VSP. Does this exist on AZE0?";
CM_ SG_ 1057 DashShifterPosition "Controls PRNDE display on dash (investigate B mode?)

0x18 = Neutral
0x08 = Park
0x20 = Drive
0x10 = Reverse
0x38 = ECO ";
CM_ BO_ 1289 "???";
CM_ SG_ 1289 TimeInSeconds "0-59";
CM_ BO_ 1290 "VCM relay from A/C Auto Amp and AC Pressor Sensor (which is measured directly from VCM) Message is identical on EV CAN and CAR CAN

AC compressor pressure goes directly into VCM, this value is only for Consult reference";
CM_ SG_ 1290 Unknown_50A_0 "04,84,85";
CM_ SG_ 1290 Unknown_50A_1 "02,13,33,40,42,53,72,73";
CM_ SG_ 1290 Unknown_50A_2 "00,a0";
CM_ SG_ 1290 ACCompressorPressure "Some sort of pressure/temperature?? 2c-44;

rises with AC on; slow decay when off";
CM_ SG_ 1290 ACStatusBits_RestUnknown "00,80  BIT1 = Rear defrost on/off";
CM_ SG_ 1290 Unknown_50A_5 "a0";
CM_ SG_ 1290 Unknown_50A_6 "04 , Only present in 2013+ (otherwise frame stops at 6bytes)";
CM_ SG_ 1290 Unknown_50A_7 "00 , Only present in 2013+ (otherwise frame stops at 6bytes)";
CM_ BO_ 1293 "???";
CM_ BO_ 1296 "VCM relay from A/C Auto Amp, to eyebrow display and A/V unit";
CM_ SG_ 1296 CounterUnknownSlow "Increments roughly every 6seconds";
CM_ SG_ 1296 CounterUnknownFast "Increments roughly every second";
CM_ SG_ 1296 ClimateControlPowerConsumption "0.25kW per lsb";
CM_ SG_ 1296 OutsideAmbientTemperature "0x92=90F;0x86=79F (90F & 79F read from dash), identical to EV CAN msg 54C byte 6";
CM_ BO_ 1354 "VCM relay from A/C Auto Amp to A/V unit for climate display";
CM_ SG_ 1354 CCStatusPlusUnknown "12,3c- CC Off; a0,da- CC On";
CM_ SG_ 1354 Unknown_54A_1 "00 (80 in 2013+)";
CM_ SG_ 1354 Unknown_54A_2 "70";
CM_ SG_ 1354 Unknown_54A_3 "06,0a,0b,0f";
CM_ SG_ 1354 ClimateControlTempSetpoint "00,39,52,53,54 (MY2011,2012)";
CM_ SG_ 1354 Unknown_54A_5 "00";
CM_ SG_ 1354 Unknown_54A_6 "00";
CM_ SG_ 1354 AmbientTempAC "Appears to track ambient (+41)

0x83=90F;0x79=79F (90F & 79F read from dash);  also some low reads at poweron

4f,8c-90";
CM_ BO_ 1355 "VCM relay from A/C Auto Amp to A/V unit for climate display";
CM_ SG_ 1355 ClimateControlStatusChange "Used to alert A/V unit that CC being toggled on or off by the user so the A/V can display the fan and CC settings on the display 00 no change, 01 change";
CM_ SG_ 1355 ClimateOnOrOffStatus1 "08 off, 78 on";
CM_ SG_ 1355 ClimateOnOrOffStatus2 "80 off, 88 on";
CM_ SG_ 1355 Unknown_54B_3 "00,08,09,10,12 observed, mostly 09 while CC on";
CM_ SG_ 1355 FanSpeedStatusChange "Used to alert A/V unit that fan speed is being changed by the user so the A/V can display the fan and CC settings on the display 00 no change, 01 change";
CM_ BO_ 1361 "??? On 370Z this message contains engine coolant temp and cruise control";
CM_ SG_ 1361 Unknown_551_4 "80 with CC on , 00 off";
CM_ BO_ 1370 "Inverter?";
CM_ SG_ 1370 UnidentifiedTemperature "InverterComBoardTemp? CabinTemperature? Very unknown.";
CM_ SG_ 1370 Unknown_55A_2 "IGBTTemperature?";
CM_ SG_ 1370 Unknown_55A_3 "IGBTDriverBoardTemperature?";
CM_ SG_ 1370 RawTemperature1 "MotorTemperature?";
CM_ BO_ 1449 "VCM to cluster?";
VAL_ 853 ClusterUnitsSelected 0 "Kilometers" 32 "Miles" ;
VAL_ 853 ClusterOdometerUnits 64 "Kilometers" 96 "Miles" ;
VAL_ 856 TurnSignalStatus 0 "BothOff" 4 "Left Signal ON" 8 "Right Signal ON" 12 "Both Signals ON (Hazards)" ;
VAL_ 1057 DashShifterPosition 24 "Neutral" 8 "Park" 32 "Drive" 16 "Reverse" 38 "ECO" ;
VAL_ 1296 ClimateControlActive 0 "CC Off" 1 "CC On" ;
VAL_ 1355 ClimateControlStatusChange 0 "No change" 1 "Changed" ;
VAL_ 1355 FanSpeedStatusChange 0 "No change" 1 "Change" ;
